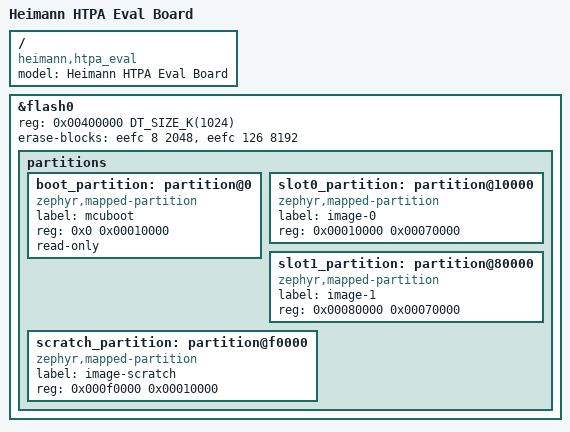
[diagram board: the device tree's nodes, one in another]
/*
 * Copyright (c) 2020 Stephanos Ioannidis <root@stephanos.io>
 * Copyright (c) 2020-2024 Gerson Fernando Budke <nandojve@gmail.com>
 * Copyright (c) 2026 sensry.io
 *
 * SPDX-License-Identifier: Apache-2.0
 */

/dts-v1/;

#include <atmel/same70x20b.dtsi>
#include "htpa_eval-common.dtsi"

/ {
	model = "Heimann HTPA Eval Board";
	compatible = "heimann,htpa_eval", "atmel,same70q20b", "atmel,same70b";
};

&flash0 {
	reg = <0x00400000 DT_SIZE_K(1024)>;
	#address-cells = <1>;
	#size-cells = <1>;
	ranges = <0x0 0x00400000 DT_SIZE_K(1024)>;
	erase-blocks = <&eefc 8 2048>, <&eefc 126 8192>;

	partitions {
		ranges;
		#address-cells = <1>;
		#size-cells = <1>;

		/* Sector 0: bootloader (64 kbytes) */
		boot_partition: partition@0 {
			compatible = "zephyr,mapped-partition";
			label = "mcuboot";
			reg = <0x0 0x00010000>;
			read-only;
		};

		/* Sector 1 to sector 7: slot0 (448 kbytes) */
		slot0_partition: partition@10000 {
			compatible = "zephyr,mapped-partition";
			label = "image-0";
			reg = <0x00010000 0x00070000>;
		};

		/* Sector 8 to sector 14: slot1 (448 kbytes) */
		slot1_partition: partition@80000 {
			compatible = "zephyr,mapped-partition";
			label = "image-1";
			reg = <0x00080000 0x00070000>;
		};

		/* Sector 15: scratch (64 kbytes) */
		scratch_partition: partition@f0000 {
			compatible = "zephyr,mapped-partition";
			label = "image-scratch";
			reg = <0x000f0000 0x00010000>;
		};
	};
};
